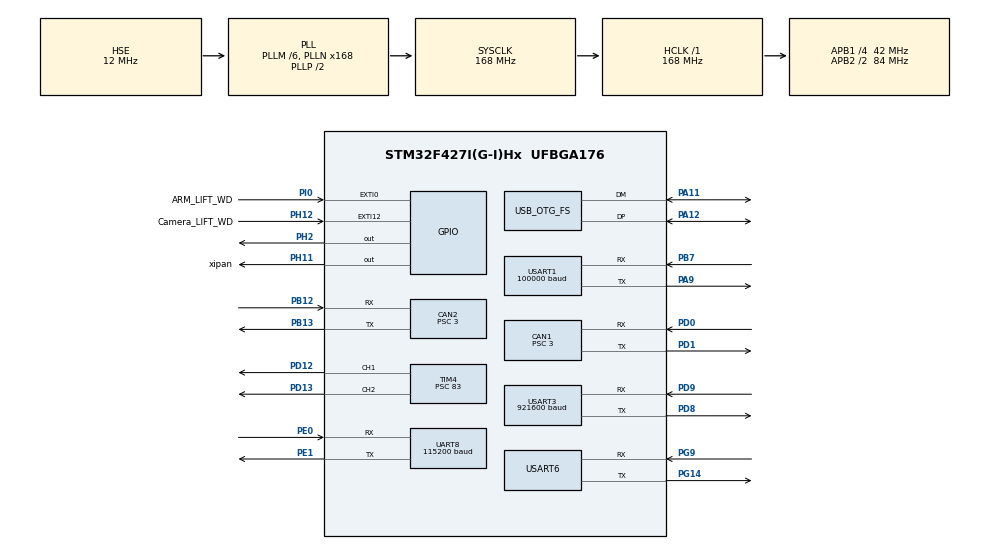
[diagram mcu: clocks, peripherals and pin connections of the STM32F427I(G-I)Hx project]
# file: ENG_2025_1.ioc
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CAN1.BS1=CAN_BS1_10TQ
CAN1.BS2=CAN_BS2_3TQ
CAN1.CalculateBaudRate=1000000
CAN1.CalculateTimeBit=1000
CAN1.CalculateTimeQuantum=71.42857142857143
CAN1.Prescaler=3
CAN2.BS1=CAN_BS1_10TQ
CAN2.BS2=CAN_BS2_3TQ
CAN2.CalculateBaudRate=1000000
CAN2.CalculateTimeBit=1000
CAN2.CalculateTimeQuantum=71.42857142857143
CAN2.Prescaler=3
Dma.Request0=UART8_RX
Dma.Request1=USART1_RX
Dma.Request2=USART3_TX
Dma.Request3=UART8_TX
Dma.Request4=USART6_RX
Dma.Request5=USART6_TX
Dma.Request6=USART3_RX
Dma.UART8_RX.0.Direction=DMA_PERIPH_TO_MEMORY
Dma.UART8_RX.0.FIFOMode=DMA_FIFOMODE_DISABLE
Dma.UART8_RX.0.Instance=DMA1_Stream6
Dma.UART8_RX.0.MemDataAlignment=DMA_MDATAALIGN_BYTE
Dma.UART8_RX.0.MemInc=DMA_MINC_ENABLE
Dma.UART8_RX.0.Mode=DMA_CIRCULAR
Dma.UART8_RX.0.PeriphDataAlignment=DMA_PDATAALIGN_BYTE
Dma.UART8_RX.0.PeriphInc=DMA_PINC_DISABLE
Dma.UART8_RX.0.Priority=DMA_PRIORITY_LOW
Dma.UART8_TX.3.Direction=DMA_MEMORY_TO_PERIPH
Dma.UART8_TX.3.FIFOMode=DMA_FIFOMODE_DISABLE
Dma.UART8_TX.3.Instance=DMA1_Stream0
Dma.UART8_TX.3.MemDataAlignment=DMA_MDATAALIGN_BYTE
Dma.UART8_TX.3.MemInc=DMA_MINC_ENABLE
Dma.UART8_TX.3.Mode=DMA_NORMAL
Dma.UART8_TX.3.PeriphDataAlignment=DMA_PDATAALIGN_BYTE
Dma.UART8_TX.3.PeriphInc=DMA_PINC_DISABLE
Dma.UART8_TX.3.Priority=DMA_PRIORITY_LOW
Dma.USART1_RX.1.Direction=DMA_PERIPH_TO_MEMORY
Dma.USART1_RX.1.FIFOMode=DMA_FIFOMODE_DISABLE
Dma.USART1_RX.1.Instance=DMA2_Stream2
Dma.USART1_RX.1.MemDataAlignment=DMA_MDATAALIGN_BYTE
Dma.USART1_RX.1.MemInc=DMA_MINC_ENABLE
Dma.USART1_RX.1.Mode=DMA_CIRCULAR
Dma.USART1_RX.1.PeriphDataAlignment=DMA_PDATAALIGN_BYTE
Dma.USART1_RX.1.PeriphInc=DMA_PINC_DISABLE
Dma.USART1_RX.1.Priority=DMA_PRIORITY_VERY_HIGH
Dma.USART3_RX.6.Direction=DMA_PERIPH_TO_MEMORY
Dma.USART3_RX.6.FIFOMode=DMA_FIFOMODE_DISABLE
Dma.USART3_RX.6.Instance=DMA1_Stream1
Dma.USART3_RX.6.MemDataAlignment=DMA_MDATAALIGN_BYTE
Dma.USART3_RX.6.MemInc=DMA_MINC_ENABLE
Dma.USART3_RX.6.Mode=DMA_CIRCULAR
Dma.USART3_RX.6.PeriphDataAlignment=DMA_PDATAALIGN_BYTE
Dma.USART3_RX.6.PeriphInc=DMA_PINC_DISABLE
Dma.USART3_RX.6.Priority=DMA_PRIORITY_LOW
Dma.USART3_TX.2.Direction=DMA_MEMORY_TO_PERIPH
Dma.USART3_TX.2.FIFOMode=DMA_FIFOMODE_DISABLE
Dma.USART3_TX.2.Instance=DMA1_Stream3
Dma.USART3_TX.2.MemDataAlignment=DMA_MDATAALIGN_BYTE
Dma.USART3_TX.2.MemInc=DMA_MINC_ENABLE
Dma.USART3_TX.2.Mode=DMA_NORMAL
Dma.USART3_TX.2.PeriphDataAlignment=DMA_PDATAALIGN_BYTE
Dma.USART3_TX.2.PeriphInc=DMA_PINC_DISABLE
Dma.USART3_TX.2.Priority=DMA_PRIORITY_LOW
Dma.USART6_RX.4.Direction=DMA_PERIPH_TO_MEMORY
Dma.USART6_RX.4.FIFOMode=DMA_FIFOMODE_DISABLE
Dma.USART6_RX.4.Instance=DMA2_Stream1
Dma.USART6_RX.4.MemDataAlignment=DMA_MDATAALIGN_BYTE
Dma.USART6_RX.4.MemInc=DMA_MINC_ENABLE
Dma.USART6_RX.4.Mode=DMA_CIRCULAR
Dma.USART6_RX.4.PeriphDataAlignment=DMA_PDATAALIGN_BYTE
Dma.USART6_RX.4.PeriphInc=DMA_PINC_DISABLE
Dma.USART6_RX.4.Priority=DMA_PRIORITY_LOW
Dma.USART6_TX.5.Direction=DMA_MEMORY_TO_PERIPH
Dma.USART6_TX.5.FIFOMode=DMA_FIFOMODE_DISABLE
Dma.USART6_TX.5.Instance=DMA2_Stream6
Dma.USART6_TX.5.MemDataAlignment=DMA_MDATAALIGN_BYTE
Dma.USART6_TX.5.MemInc=DMA_MINC_ENABLE
Dma.USART6_TX.5.Mode=DMA_NORMAL
Dma.USART6_TX.5.PeriphDataAlignment=DMA_PDATAALIGN_BYTE
Dma.USART6_TX.5.PeriphInc=DMA_PINC_DISABLE
Dma.USART6_TX.5.Priority=DMA_PRIORITY_LOW
FREERTOS.Tasks01=Arm_Ctrl,24,128,Arm_Ctrl_Task,As weak,NULL,Dynamic,NULL,NULL;Moto,24,128,MotoTask,As weak,NULL,Dynamic,NULL,NULL;Mode,24,128,ModeTask,As weak,NULL,Dynamic,NULL,NULL;Transmit,24,128,TransmitTask,As weak,NULL,Dynamic,NULL,NULL;Lift,8,128,LiftTask,As weak,NULL,Dynamic,NULL,NULL;USB,48,1024,usb_task,As weak,NULL,Dynamic,NULL,NULL;SelfCheck,24,128,SelfCheck_mode,As weak,NULL,Dynamic,NULL,NULL;UI,24,128,ui_task,As weak,NULL,Dynamic,NULL,NULL
Mcu.Family=STM32F4
Mcu.Name=STM32F427I(G-I)Hx
Mcu.Package=UFBGA176
NVIC.CAN1_RX0_IRQn=true\:5\:0\:false\:false\:true\:true\:true\:true\:true
NVIC.CAN1_RX1_IRQn=true\:5\:0\:false\:false\:true\:true\:true\:true\:true
NVIC.CAN2_RX0_IRQn=true\:5\:0\:false\:false\:true\:true\:true\:true\:true
NVIC.CAN2_RX1_IRQn=true\:5\:0\:false\:false\:true\:true\:true\:true\:true
NVIC.DMA1_Stream0_IRQn=true\:5\:0\:false\:false\:true\:true\:false\:true\:true
NVIC.DMA1_Stream1_IRQn=true\:5\:0\:false\:false\:true\:true\:false\:true\:true
NVIC.DMA1_Stream3_IRQn=true\:5\:0\:false\:false\:true\:true\:false\:true\:true
NVIC.DMA1_Stream6_IRQn=true\:5\:0\:false\:false\:true\:true\:false\:true\:true
NVIC.DMA2_Stream1_IRQn=true\:5\:0\:false\:false\:true\:true\:false\:true\:true
NVIC.DMA2_Stream2_IRQn=true\:5\:0\:false\:false\:true\:true\:false\:true\:true
NVIC.DMA2_Stream6_IRQn=true\:5\:0\:false\:false\:true\:true\:false\:true\:true
NVIC.EXTI0_IRQn=true\:5\:0\:false\:false\:true\:true\:true\:true\:true
NVIC.EXTI15_10_IRQn=true\:5\:0\:false\:false\:true\:true\:true\:true\:true
NVIC.OTG_FS_IRQn=true\:5\:0\:false\:false\:true\:true\:false\:true\:true
NVIC.PriorityGroup=NVIC_PRIORITYGROUP_4
NVIC.TIM7_IRQn=true\:15\:0\:false\:false\:true\:false\:false\:true\:true
NVIC.TimeBase=TIM7_IRQn
NVIC.TimeBaseIP=TIM7
NVIC.UART8_IRQn=true\:5\:0\:false\:false\:true\:true\:true\:true\:true
NVIC.USART1_IRQn=true\:5\:0\:false\:false\:true\:true\:true\:true\:true
NVIC.USART3_IRQn=true\:5\:0\:false\:false\:true\:true\:true\:true\:true
NVIC.USART6_IRQn=true\:5\:0\:false\:false\:true\:true\:false\:true\:true
PA11.Mode=Device_Only
PA11.Signal=USB_OTG_FS_DM
PA12.Mode=Device_Only
PA12.Signal=USB_OTG_FS_DP
PA13.Mode=Serial_Wire
PA13.Signal=SYS_JTMS-SWDIO
PA14.Mode=Serial_Wire
PA14.Signal=SYS_JTCK-SWCLK
PA9.Mode=Asynchronous
PA9.Signal=USART1_TX
PB12.Mode=CAN_Activate
PB12.Signal=CAN2_RX
PB13.Mode=CAN_Activate
PB13.Signal=CAN2_TX
PB7.Mode=Asynchronous
PB7.Signal=USART1_RX
PD0.Mode=CAN_Activate
PD0.Signal=CAN1_RX
PD1.Mode=CAN_Activate
PD1.Signal=CAN1_TX
PD12.Signal=S_TIM4_CH1
PD13.Signal=S_TIM4_CH2
PD8.Mode=Asynchronous
PD8.Signal=USART3_TX
PD9.Mode=Asynchronous
PD9.Signal=USART3_RX
PE0.Mode=Asynchronous
PE0.Signal=UART8_RX
PE1.Mode=Asynchronous
PE1.Signal=UART8_TX
PG14.Mode=Asynchronous
PG14.Signal=USART6_TX
PG9.Mode=Asynchronous
PG9.Signal=USART6_RX
PH0/OSC_IN.Mode=HSE-External-Oscillator
PH0/OSC_IN.Signal=RCC_OSC_IN
PH1/OSC_OUT.Mode=HSE-External-Oscillator
PH1/OSC_OUT.Signal=RCC_OSC_OUT
PH11.GPIO_Label=xipan
PH11.GPIO_PuPd=GPIO_PULLDOWN
PH11.Signal=GPIO_Output
PH12.GPIO_Label=Camera_LIFT_WD
PH12.GPIO_ModeDefaultEXTI=GPIO_MODE_IT_RISING_FALLING
PH12.GPIO_PuPd=GPIO_PULLDOWN
PH12.Signal=GPXTI12
PH2.Signal=GPIO_Output
PI0.GPIO_Label=ARM_LIFT_WD
PI0.GPIO_ModeDefaultEXTI=GPIO_MODE_IT_RISING_FALLING
PI0.GPIO_PuPd=GPIO_PULLDOWN
PI0.Signal=GPXTI0
ProjectManager.HeapSize=0x200
ProjectManager.StackSize=0x400
ProjectManager.TargetToolchain=MDK-ARM V5.32
RCC.48MHZClocksFreq_Value=48000000
RCC.AHBFreq_Value=168000000
RCC.APB1CLKDivider=RCC_HCLK_DIV4
RCC.APB1Freq_Value=42000000
RCC.APB1TimFreq_Value=84000000
RCC.APB2CLKDivider=RCC_HCLK_DIV2
RCC.APB2Freq_Value=84000000
RCC.APB2TimFreq_Value=168000000
RCC.CortexFreq_Value=168000000
RCC.HCLKFreq_Value=168000000
RCC.HSE_VALUE=12000000
RCC.HSI_VALUE=16000000
RCC.LSE_VALUE=32768
RCC.PLLM=6
RCC.PLLN=168
RCC.PLLQ=7
RCC.SYSCLKFreq_VALUE=168000000
RCC.SYSCLKSource=RCC_SYSCLKSOURCE_PLLCLK
RCC.VCOOutputFreq_Value=336000000
SH.S_TIM4_CH1.0=TIM4_CH1,PWM Generation1 CH1
SH.S_TIM4_CH2.0=TIM4_CH2,PWM Generation2 CH2
TIM2.AutoReloadPreload=TIM_AUTORELOAD_PRELOAD_ENABLE
TIM2.Period=0xffffffff
TIM2.Prescaler=84-1
TIM4.Channel-PWM\ Generation1\ CH1=TIM_CHANNEL_1
TIM4.Channel-PWM\ Generation2\ CH2=TIM_CHANNEL_2
TIM4.Period=20000
TIM4.Prescaler=83
UART8.BaudRate=115200
UART8.VirtualMode=Asynchronous
USART1.BaudRate=100000
USART1.Mode=MODE_RX
USART1.Parity=PARITY_EVEN
USART1.VirtualMode=VM_ASYNC
USART3.BaudRate=921600
USART3.VirtualMode=VM_ASYNC
USART6.VirtualMode=VM_ASYNC
USB_DEVICE.CLASS_NAME_FS=CDC
USB_DEVICE.MANUFACTURER_STRING-CDC_FS=RM
USB_DEVICE.PID_CDC_FS=0x514
USB_DEVICE.PRODUCT_STRING_CDC_FS=Robot
USB_DEVICE.VID-CDC_FS=0x114
USB_DEVICE.VirtualMode-CDC_FS=Cdc
USB_DEVICE.VirtualModeFS=Cdc_FS
USB_OTG_FS.VirtualMode=Device_Only
VP_FREERTOS_VS_CMSIS_V2.Mode=CMSIS_V2
VP_SYS_VS_tim7.Mode=TIM7
VP_TIM2_VS_ClockSourceINT.Mode=Internal
VP_USB_DEVICE_VS_USB_DEVICE_CDC_FS.Mode=CDC_FS
board=custom

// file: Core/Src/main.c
/* USER CODE BEGIN Header */
/**
  ******************************************************************************
  * @file           : main.c
  * @brief          : Main program body
  ******************************************************************************
  * @attention
  *
  * Copyright (c) 2025 STMicroelectronics.
  * All rights reserved.
  *
  * This software is licensed under terms that can be found in the LICENSE file
  * in the root directory of this software component.
  * If no LICENSE file comes with this software, it is provided AS-IS.
  *
  ******************************************************************************
  */
/* USER CODE END Header */
#include "main.h"
#include "cmsis_os.h"
#include "can.h"
#include "dma.h"
#include "tim.h"
#include "usart.h"
#include "usb_device.h"
#include "gpio.h"

/* USER CODE BEGIN Includes */

#include "includes.h"

/* USER CODE END Includes */

void SystemClock_Config(void);
void MX_FREERTOS_Init(void);

int main(void)
{

  /* MCU Configuration--------------------------------------------------------*/

  /* Reset of all peripherals, Initializes the Flash interface and the Systick. */
  HAL_Init();

  /* Configure the system clock */
  SystemClock_Config();

  /* Initialize all configured peripherals */
  MX_GPIO_Init();
  MX_DMA_Init();
  MX_CAN1_Init();
  MX_CAN2_Init();
  MX_TIM2_Init();
  MX_UART8_Init();
  MX_USART1_UART_Init();
  MX_USART3_UART_Init();
  MX_USART6_UART_Init();
  MX_TIM4_Init();
  /* USER CODE BEGIN 2 */
	usb_init();
  can_filter_init();
	__HAL_TIM_ENABLE(&htim2);
	PWM_Start();
//	wd_init();
  /* USER CODE END 2 */

  /* Init scheduler */
  osKernelInitialize();  /* Call init function for freertos objects (in cmsis_os2.c) */
  MX_FREERTOS_Init();

  /* Start scheduler */
  osKernelStart();

  /* We should never get here as control is now taken by the scheduler */

  /* Infinite loop */
  while (1)
  {

  }
}

void SystemClock_Config(void)
{
  RCC_OscInitTypeDef RCC_OscInitStruct = {0};
  RCC_ClkInitTypeDef RCC_ClkInitStruct = {0};

  /** Configure the main internal regulator output voltage
  */
  __HAL_RCC_PWR_CLK_ENABLE();
  __HAL_PWR_VOLTAGESCALING_CONFIG(PWR_REGULATOR_VOLTAGE_SCALE1);

  /** Initializes the RCC Oscillators according to the specified parameters
  * in the RCC_OscInitTypeDef structure.
  */
  RCC_OscInitStruct.OscillatorType = RCC_OSCILLATORTYPE_HSE;
  RCC_OscInitStruct.HSEState = RCC_HSE_ON;
  RCC_OscInitStruct.PLL.PLLState = RCC_PLL_ON;
  RCC_OscInitStruct.PLL.PLLSource = RCC_PLLSOURCE_HSE;
  RCC_OscInitStruct.PLL.PLLM = 6;
  RCC_OscInitStruct.PLL.PLLN = 168;
  RCC_OscInitStruct.PLL.PLLP = RCC_PLLP_DIV2;
  RCC_OscInitStruct.PLL.PLLQ = 7;
  if (HAL_RCC_OscConfig(&RCC_OscInitStruct) != HAL_OK)
  {
    Error_Handler();
  }

  /** Initializes the CPU, AHB and APB buses clocks
  */
  RCC_ClkInitStruct.ClockType = RCC_CLOCKTYPE_HCLK|RCC_CLOCKTYPE_SYSCLK
                              |RCC_CLOCKTYPE_PCLK1|RCC_CLOCKTYPE_PCLK2;
  RCC_ClkInitStruct.SYSCLKSource = RCC_SYSCLKSOURCE_PLLCLK;
  RCC_ClkInitStruct.AHBCLKDivider = RCC_SYSCLK_DIV1;
  RCC_ClkInitStruct.APB1CLKDivider = RCC_HCLK_DIV4;
  RCC_ClkInitStruct.APB2CLKDivider = RCC_HCLK_DIV2;

  if (HAL_RCC_ClockConfig(&RCC_ClkInitStruct, FLASH_LATENCY_5) != HAL_OK)
  {
    Error_Handler();
  }
}

void HAL_TIM_PeriodElapsedCallback(TIM_HandleTypeDef *htim)
{
  if (htim->Instance == TIM7)
  {
    HAL_IncTick();
  }
}

void Error_Handler(void)
{
  __disable_irq();
  while (1)
  {
  }
}

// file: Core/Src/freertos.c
/* USER CODE BEGIN Header */
/**
  ******************************************************************************
  * File Name          : freertos.c
  * Description        : Code for freertos applications
  ******************************************************************************
  * @attention
  *
  * Copyright (c) 2025 STMicroelectronics.
  * All rights reserved.
  *
  * This software is licensed under terms that can be found in the LICENSE file
  * in the root directory of this software component.
  * If no LICENSE file comes with this software, it is provided AS-IS.
  *
  ******************************************************************************
  */
/* USER CODE END Header */

#include "FreeRTOS.h"
#include "task.h"
#include "main.h"
#include "cmsis_os.h"

/* Definitions for Arm_Ctrl */
osThreadId_t Arm_CtrlHandle;
const osThreadAttr_t Arm_Ctrl_attributes = {
  .name = "Arm_Ctrl",
  .stack_size = 128 * 4,
  .priority = (osPriority_t) osPriorityNormal,
};
/* Definitions for Moto */
osThreadId_t MotoHandle;
const osThreadAttr_t Moto_attributes = {
  .name = "Moto",
  .stack_size = 128 * 4,
  .priority = (osPriority_t) osPriorityNormal,
};
/* Definitions for Mode */
osThreadId_t ModeHandle;
const osThreadAttr_t Mode_attributes = {
  .name = "Mode",
  .stack_size = 128 * 4,
  .priority = (osPriority_t) osPriorityNormal,
};
/* Definitions for Transmit */
osThreadId_t TransmitHandle;
const osThreadAttr_t Transmit_attributes = {
  .name = "Transmit",
  .stack_size = 128 * 4,
  .priority = (osPriority_t) osPriorityNormal,
};
/* Definitions for Lift */
osThreadId_t LiftHandle;
const osThreadAttr_t Lift_attributes = {
  .name = "Lift",
  .stack_size = 128 * 4,
  .priority = (osPriority_t) osPriorityLow,
};
/* Definitions for USB */
osThreadId_t USBHandle;
const osThreadAttr_t USB_attributes = {
  .name = "USB",
  .stack_size = 1024 * 4,
  .priority = (osPriority_t) osPriorityRealtime,
};
/* Definitions for SelfCheck */
osThreadId_t SelfCheckHandle;
const osThreadAttr_t SelfCheck_attributes = {
  .name = "SelfCheck",
  .stack_size = 128 * 4,
  .priority = (osPriority_t) osPriorityNormal,
};
/* Definitions for UI */
osThreadId_t UIHandle;
const osThreadAttr_t UI_attributes = {
  .name = "UI",
  .stack_size = 128 * 4,
  .priority = (osPriority_t) osPriorityNormal,
};

void Arm_Ctrl_Task(void *argument);
void MotoTask(void *argument);
void ModeTask(void *argument);
void TransmitTask(void *argument);
void LiftTask(void *argument);
void usb_task(void *argument);
void SelfCheck_mode(void *argument);
void ui_task(void *argument);

extern void MX_USB_DEVICE_Init(void);
void MX_FREERTOS_Init(void); /* (MISRA C 2004 rule 8.1) */

void MX_FREERTOS_Init(void) {

  /* Create the thread(s) */
  /* creation of Arm_Ctrl */
  Arm_CtrlHandle = osThreadNew(Arm_Ctrl_Task, NULL, &Arm_Ctrl_attributes);

  /* creation of Moto */
  MotoHandle = osThreadNew(MotoTask, NULL, &Moto_attributes);

  /* creation of Mode */
  ModeHandle = osThreadNew(ModeTask, NULL, &Mode_attributes);

  /* creation of Transmit */
  TransmitHandle = osThreadNew(TransmitTask, NULL, &Transmit_attributes);

  /* creation of Lift */
  LiftHandle = osThreadNew(LiftTask, NULL, &Lift_attributes);

  /* creation of USB */
  USBHandle = osThreadNew(usb_task, NULL, &USB_attributes);

  /* creation of SelfCheck */
  SelfCheckHandle = osThreadNew(SelfCheck_mode, NULL, &SelfCheck_attributes);

  /* creation of UI */
  UIHandle = osThreadNew(ui_task, NULL, &UI_attributes);

}

__weak void Arm_Ctrl_Task(void *argument)
{
  /* init code for USB_DEVICE */
  MX_USB_DEVICE_Init();
  for(;;)
  {
    osDelay(1);
  }
}

__weak void MotoTask(void *argument)
{
  for(;;)
  {
    osDelay(1);
  }
}

__weak void ModeTask(void *argument)
{
  for(;;)
  {
    osDelay(1);
  }
}

__weak void TransmitTask(void *argument)
{
  for(;;)
  {
    osDelay(1);
  }
}

__weak void LiftTask(void *argument)
{
  for(;;)
  {
    osDelay(1);
  }
}

__weak void usb_task(void *argument)
{
  for(;;)
  {
    osDelay(1);
  }
}

__weak void SelfCheck_mode(void *argument)
{
  for(;;)
  {
    osDelay(1);
  }
}

__weak void ui_task(void *argument)
{
  for(;;)
  {
    osDelay(1);
  }
}
